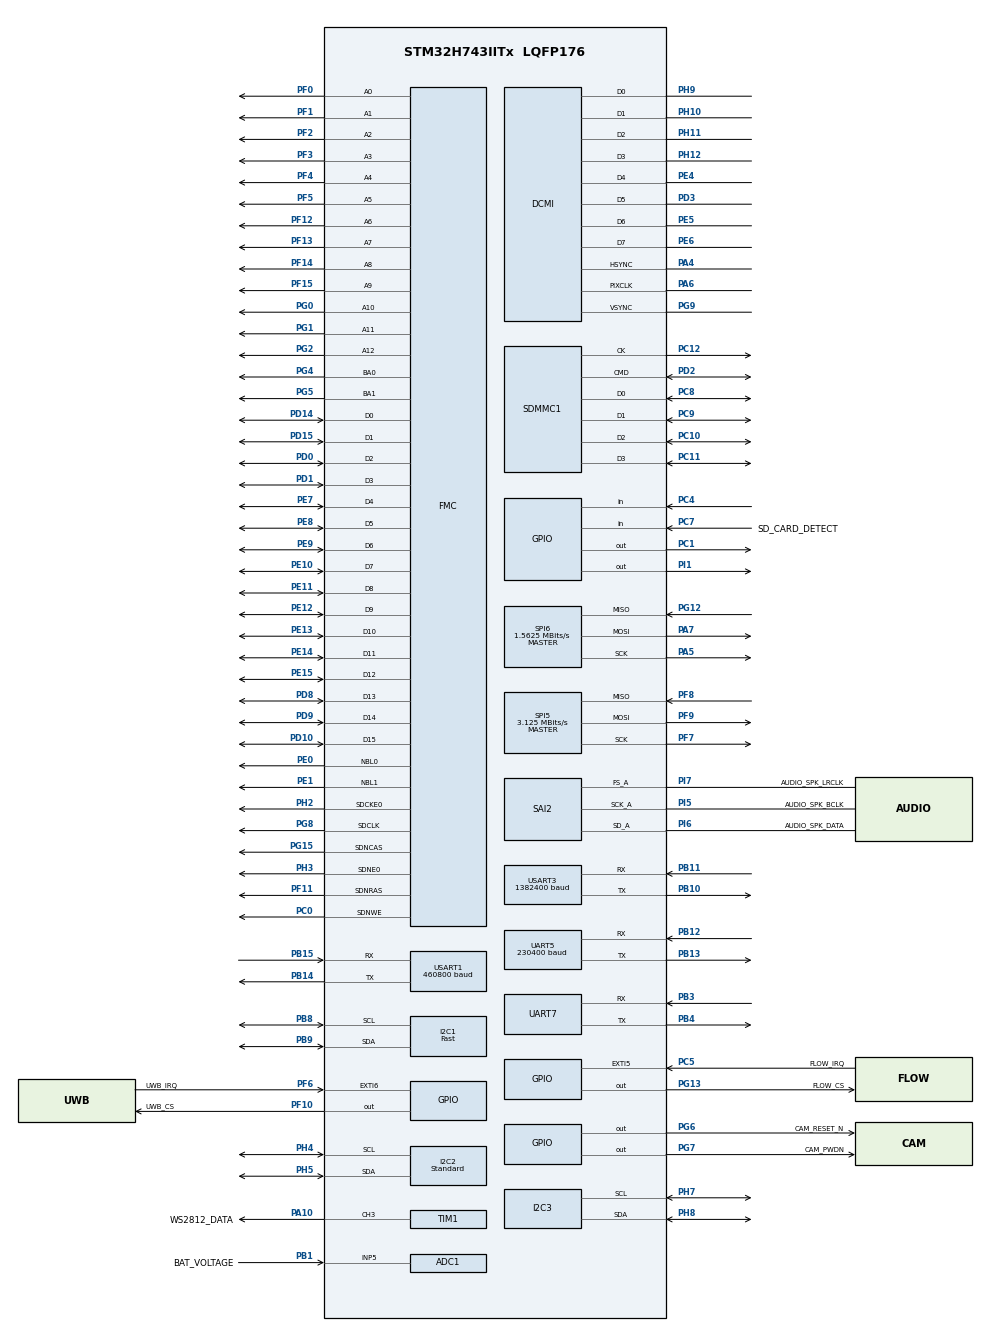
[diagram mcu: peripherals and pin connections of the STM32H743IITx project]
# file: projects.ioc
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ADC1.Channel-1\#ChannelRegularConversion=ADC_CHANNEL_5
ADC1.ClockPrescaler=ADC_CLOCK_ASYNC_DIV4
ADC1.NbrOfConversionFlag=1
ADC1.OffsetNumber-1\#ChannelRegularConversion=ADC_OFFSET_NONE
ADC1.OffsetSignedSaturation-1\#ChannelRegularConversion=DISABLE
ADC1.Rank-1\#ChannelRegularConversion=1
ADC1.SamplingTime-1\#ChannelRegularConversion=ADC_SAMPLETIME_387CYCLES_5
ADC1.master=1
CORTEX_M7.CPU_DCache=Disabled
CORTEX_M7.CPU_ICache=Enabled
CORTEX_M7.default_mode_Activation=1
DCMI.ByteSelectMode=DCMI_BSM_ALL
DCMI.CaptureRate=DCMI_CR_ALL_FRAME
DCMI.HSPolarity=DCMI_HSPOLARITY_LOW
DCMI.JPEGMode=DCMI_JPEG_ENABLE
DCMI.LineSelectMode=DCMI_LSM_ALL
DCMI.PCKPolarity=DCMI_PCKPOLARITY_RISING
DCMI.VSPolarity=DCMI_VSPOLARITY_LOW
Dma.DCMI.0.Direction=DMA_PERIPH_TO_MEMORY
Dma.DCMI.0.EventEnable=DISABLE
Dma.DCMI.0.FIFOMode=DMA_FIFOMODE_ENABLE
Dma.DCMI.0.FIFOThreshold=DMA_FIFO_THRESHOLD_FULL
Dma.DCMI.0.Instance=DMA1_Stream0
Dma.DCMI.0.MemBurst=DMA_MBURST_INC4
Dma.DCMI.0.MemDataAlignment=DMA_MDATAALIGN_WORD
Dma.DCMI.0.MemInc=DMA_MINC_ENABLE
Dma.DCMI.0.Mode=DMA_NORMAL
Dma.DCMI.0.PeriphBurst=DMA_PBURST_SINGLE
Dma.DCMI.0.PeriphDataAlignment=DMA_PDATAALIGN_WORD
Dma.DCMI.0.PeriphInc=DMA_PINC_DISABLE
Dma.DCMI.0.Polarity=HAL_DMAMUX_REQ_GEN_RISING
Dma.DCMI.0.Priority=DMA_PRIORITY_VERY_HIGH
Dma.DCMI.0.RequestNumber=1
Dma.DCMI.0.SignalID=NONE
Dma.DCMI.0.SyncEnable=DISABLE
Dma.DCMI.0.SyncPolarity=HAL_DMAMUX_SYNC_NO_EVENT
Dma.DCMI.0.SyncRequestNumber=1
Dma.DCMI.0.SyncSignalID=NONE
Dma.Request0=DCMI
Dma.Request1=SAI2_A
Dma.Request2=TIM1_CH3
Dma.Request3=USART1_RX
Dma.Request4=USART1_TX
Dma.Request5=UART5_RX
Dma.SAI2_A.1.Direction=DMA_MEMORY_TO_PERIPH
Dma.SAI2_A.1.EventEnable=DISABLE
Dma.SAI2_A.1.FIFOMode=DMA_FIFOMODE_DISABLE
Dma.SAI2_A.1.Instance=DMA1_Stream4
Dma.SAI2_A.1.MemDataAlignment=DMA_MDATAALIGN_HALFWORD
Dma.SAI2_A.1.MemInc=DMA_MINC_ENABLE
Dma.SAI2_A.1.Mode=DMA_CIRCULAR
Dma.SAI2_A.1.PeriphDataAlignment=DMA_PDATAALIGN_HALFWORD
Dma.SAI2_A.1.PeriphInc=DMA_PINC_DISABLE
Dma.SAI2_A.1.Polarity=HAL_DMAMUX_REQ_GEN_RISING
Dma.SAI2_A.1.Priority=DMA_PRIORITY_HIGH
Dma.SAI2_A.1.RequestNumber=1
Dma.SAI2_A.1.SignalID=NONE
Dma.SAI2_A.1.SyncEnable=DISABLE
Dma.SAI2_A.1.SyncPolarity=HAL_DMAMUX_SYNC_NO_EVENT
Dma.SAI2_A.1.SyncRequestNumber=1
Dma.SAI2_A.1.SyncSignalID=NONE
Dma.TIM1_CH3.2.Direction=DMA_MEMORY_TO_PERIPH
Dma.TIM1_CH3.2.EventEnable=DISABLE
Dma.TIM1_CH3.2.FIFOMode=DMA_FIFOMODE_DISABLE
Dma.TIM1_CH3.2.Instance=DMA1_Stream3
Dma.TIM1_CH3.2.MemDataAlignment=DMA_MDATAALIGN_HALFWORD
Dma.TIM1_CH3.2.MemInc=DMA_MINC_ENABLE
Dma.TIM1_CH3.2.Mode=DMA_NORMAL
Dma.TIM1_CH3.2.PeriphDataAlignment=DMA_PDATAALIGN_HALFWORD
Dma.TIM1_CH3.2.PeriphInc=DMA_PINC_DISABLE
Dma.TIM1_CH3.2.Polarity=HAL_DMAMUX_REQ_GEN_RISING
Dma.TIM1_CH3.2.Priority=DMA_PRIORITY_HIGH
Dma.TIM1_CH3.2.RequestNumber=1
Dma.TIM1_CH3.2.SignalID=NONE
Dma.TIM1_CH3.2.SyncEnable=DISABLE
Dma.TIM1_CH3.2.SyncPolarity=HAL_DMAMUX_SYNC_NO_EVENT
Dma.TIM1_CH3.2.SyncRequestNumber=1
Dma.TIM1_CH3.2.SyncSignalID=NONE
Dma.UART5_RX.5.Direction=DMA_PERIPH_TO_MEMORY
Dma.UART5_RX.5.EventEnable=DISABLE
Dma.UART5_RX.5.FIFOMode=DMA_FIFOMODE_DISABLE
Dma.UART5_RX.5.Instance=DMA1_Stream5
Dma.UART5_RX.5.MemDataAlignment=DMA_MDATAALIGN_BYTE
Dma.UART5_RX.5.MemInc=DMA_MINC_ENABLE
Dma.UART5_RX.5.Mode=DMA_CIRCULAR
Dma.UART5_RX.5.PeriphDataAlignment=DMA_PDATAALIGN_BYTE
Dma.UART5_RX.5.PeriphInc=DMA_PINC_DISABLE
Dma.UART5_RX.5.Polarity=HAL_DMAMUX_REQ_GEN_RISING
Dma.UART5_RX.5.Priority=DMA_PRIORITY_LOW
Dma.UART5_RX.5.RequestNumber=1
Dma.UART5_RX.5.SignalID=NONE
Dma.UART5_RX.5.SyncEnable=DISABLE
Dma.UART5_RX.5.SyncPolarity=HAL_DMAMUX_SYNC_NO_EVENT
Dma.UART5_RX.5.SyncRequestNumber=1
Dma.UART5_RX.5.SyncSignalID=NONE
Dma.USART1_RX.3.Direction=DMA_PERIPH_TO_MEMORY
Dma.USART1_RX.3.EventEnable=DISABLE
Dma.USART1_RX.3.FIFOMode=DMA_FIFOMODE_DISABLE
Dma.USART1_RX.3.Instance=DMA1_Stream1
Dma.USART1_RX.3.MemDataAlignment=DMA_MDATAALIGN_BYTE
Dma.USART1_RX.3.MemInc=DMA_MINC_ENABLE
Dma.USART1_RX.3.Mode=DMA_CIRCULAR
Dma.USART1_RX.3.PeriphDataAlignment=DMA_PDATAALIGN_BYTE
Dma.USART1_RX.3.PeriphInc=DMA_PINC_DISABLE
Dma.USART1_RX.3.Polarity=HAL_DMAMUX_REQ_GEN_RISING
Dma.USART1_RX.3.Priority=DMA_PRIORITY_HIGH
Dma.USART1_RX.3.RequestNumber=1
Dma.USART1_RX.3.SignalID=NONE
Dma.USART1_RX.3.SyncEnable=DISABLE
Dma.USART1_RX.3.SyncPolarity=HAL_DMAMUX_SYNC_NO_EVENT
Dma.USART1_RX.3.SyncRequestNumber=1
Dma.USART1_RX.3.SyncSignalID=NONE
Dma.USART1_TX.4.Direction=DMA_MEMORY_TO_PERIPH
Dma.USART1_TX.4.EventEnable=DISABLE
Dma.USART1_TX.4.FIFOMode=DMA_FIFOMODE_DISABLE
Dma.USART1_TX.4.Instance=DMA1_Stream2
Dma.USART1_TX.4.MemDataAlignment=DMA_MDATAALIGN_BYTE
Dma.USART1_TX.4.MemInc=DMA_MINC_ENABLE
Dma.USART1_TX.4.Mode=DMA_NORMAL
Dma.USART1_TX.4.PeriphDataAlignment=DMA_PDATAALIGN_BYTE
Dma.USART1_TX.4.PeriphInc=DMA_PINC_DISABLE
Dma.USART1_TX.4.Polarity=HAL_DMAMUX_REQ_GEN_RISING
Dma.USART1_TX.4.Priority=DMA_PRIORITY_LOW
Dma.USART1_TX.4.RequestNumber=1
Dma.USART1_TX.4.SignalID=NONE
Dma.USART1_TX.4.SyncEnable=DISABLE
Dma.USART1_TX.4.SyncPolarity=HAL_DMAMUX_SYNC_NO_EVENT
Dma.USART1_TX.4.SyncRequestNumber=1
Dma.USART1_TX.4.SyncSignalID=NONE
FATFS.USE_DMA_CODE_SD=1
FATFS._FS_NORTC=1
FATFS._FS_REENTRANT=1
FATFS._FS_LOCK=4
FATFS._MAX_SS=512
FATFS._MIN_SS=512
FATFS._NORTC_MDAY=8
FATFS._NORTC_MON=10
FATFS._NORTC_YEAR=2026
FATFS._USE_LFN=0
FMC.CASLatency1=FMC_SDRAM_CAS_LATENCY_2
FMC.ColumnBitsNumber1=FMC_SDRAM_COLUMN_BITS_NUM_9
FMC.ExitSelfRefreshDelay1=8
FMC.LoadToActiveDelay1=2
FMC.RCDDelay1=2
FMC.RPDelay1=2
FMC.ReadBurst1=FMC_SDRAM_RBURST_ENABLE
FMC.ReadPipeDelay1=FMC_SDRAM_RPIPE_DELAY_1
FMC.RowBitsNumber1=FMC_SDRAM_ROW_BITS_NUM_13
FMC.RowCycleDelay1=7
FMC.SDClockPeriod1=FMC_SDRAM_CLOCK_PERIOD_2
FMC.SDClockPeriod2=FMC_SDRAM_CLOCK_PERIOD_2
FMC.SelfRefreshTime1=5
FMC.WriteRecoveryTime1=3
FREERTOS.Mutexes01=i2c1Mutex,Dynamic,NULL
FREERTOS.Tasks01=defaultTask,24,512,StartDefaultTask,Default,NULL,Dynamic,NULL,NULL;uart_bluetooth,8,512,BLUETOOTH,Default,NULL,Dynamic,NULL,NULL;led_blink,8,128,led_blink1,Default,NULL,Dynamic,NULL,NULL;mavlinkTask,32,1024,StartMavlinkTask,Default,NULL,Dynamic,NULL,NULL;gpsTask,24,512,StartGpsTask,Default,NULL,Dynamic,NULL,NULL;audio1,24,512,audio,Default,NULL,Dynamic,NULL,NULL;thermalTask,8,2048,StartThermalTask,Default,NULL,Dynamic,NULL,NULL
FREERTOS.configCHECK_FOR_STACK_OVERFLOW=2
FREERTOS.configTOTAL_HEAP_SIZE=98304
FREERTOS.configUSE_MALLOC_FAILED_HOOK=1
FREERTOS.configUSE_NEWLIB_REENTRANT=0
I2C1.I2C_Speed_Mode=I2C_Fast
I2C1.Speed=400
I2C1.Timing=0x009034B6
I2C2.I2C_Fall_Time=100
I2C2.I2C_Rise_Time=100
I2C2.I2C_Speed_Mode=I2C_Standard
I2C2.Speed=100
I2C2.Timing=0x20B182BE
I2C3.Timing=0x10C0ECFF
Mcu.Family=STM32H7
Mcu.Name=STM32H743IITx
Mcu.Package=LQFP176
NVIC.DCMI_IRQn=true\:5\:0\:false\:false\:true\:true\:false\:true\:true
NVIC.DMA1_Stream0_IRQn=true\:5\:0\:false\:false\:true\:true\:false\:true\:true
NVIC.DMA1_Stream1_IRQn=true\:5\:0\:false\:false\:true\:true\:false\:true\:true
NVIC.DMA1_Stream2_IRQn=true\:5\:0\:false\:false\:true\:true\:false\:true\:true
NVIC.DMA1_Stream3_IRQn=true\:5\:0\:false\:false\:true\:true\:false\:true\:true
NVIC.DMA1_Stream4_IRQn=true\:5\:0\:false\:false\:true\:true\:false\:true\:true
NVIC.DMA1_Stream5_IRQn=true\:5\:0\:false\:false\:true\:true\:false\:true\:true
NVIC.EXTI9_5_IRQn=true\:5\:0\:false\:false\:true\:true\:false\:true\:true
NVIC.PriorityGroup=NVIC_PRIORITYGROUP_4
NVIC.SDMMC1_IRQn=true\:5\:0\:false\:false\:true\:true\:false\:true\:true
NVIC.TIM2_IRQn=true\:15\:0\:false\:false\:true\:false\:false\:true\:true
NVIC.TimeBase=TIM2_IRQn
NVIC.TimeBaseIP=TIM2
NVIC.UART5_IRQn=true\:5\:0\:false\:false\:true\:true\:false\:true\:true
NVIC.UART7_IRQn=true\:5\:0\:false\:false\:true\:true\:false\:true\:true
NVIC.USART1_IRQn=true\:5\:0\:false\:false\:true\:true\:false\:true\:true
PA10.GPIO_Label=WS2812_DATA
PA10.GPIO_Speed=GPIO_SPEED_FREQ_HIGH
PA10.Signal=S_TIM1_CH3
PA13\ (JTMS/SWDIO).Mode=Serial_Wire
PA13\ (JTMS/SWDIO).Signal=DEBUG_JTMS-SWDIO
PA14\ (JTCK/SWCLK).Mode=Serial_Wire
PA14\ (JTCK/SWCLK).Signal=DEBUG_JTCK-SWCLK
PA4.Mode=Slave_8_bits_External_Synchro
PA4.Signal=DCMI_HSYNC
PA5.Mode=Full_Duplex_Master
PA5.Signal=SPI6_SCK
PA6.Mode=Slave_8_bits_External_Synchro
PA6.Signal=DCMI_PIXCLK
PA7.Mode=Full_Duplex_Master
PA7.Signal=SPI6_MOSI
PB1.GPIO_Label=BAT_VOLTAGE
PB1.Signal=ADCx_INP5
PB10.Mode=Asynchronous
PB10.Signal=USART3_TX
PB11.Mode=Asynchronous
PB11.Signal=USART3_RX
PB12.Mode=Asynchronous
PB12.Signal=UART5_RX
PB13.Mode=Asynchronous
PB13.Signal=UART5_TX
PB14.Mode=Asynchronous
PB14.Signal=USART1_TX
PB15.Mode=Asynchronous
PB15.Signal=USART1_RX
PB3\ (JTDO/TRACESWO).Mode=Asynchronous
PB3\ (JTDO/TRACESWO).Signal=UART7_RX
PB4\ (NJTRST).Mode=Asynchronous
PB4\ (NJTRST).Signal=UART7_TX
PB8.Mode=I2C
PB8.Signal=I2C1_SCL
PB9.Mode=I2C
PB9.Signal=I2C1_SDA
PC0.Signal=FMC_SDNWE
PC1.GPIO_ModeDefaultOutputPP=GPIO_MODE_OUTPUT_OD
PC1.GPIO_PuPd=GPIO_NOPULL
PC1.PinState=GPIO_PIN_RESET
PC1.Signal=GPIO_Output
PC10.Mode=SD_4_bits_Wide_bus
PC10.Signal=SDMMC1_D2
PC11.Mode=SD_4_bits_Wide_bus
PC11.Signal=SDMMC1_D3
PC12.Mode=SD_4_bits_Wide_bus
PC12.Signal=SDMMC1_CK
PC4.GPIO_PuPd=GPIO_PULLUP
PC4.Signal=GPIO_Input
PC5.GPIO_Label=FLOW_IRQ
PC5.GPIO_ModeDefaultEXTI=GPIO_MODE_IT_FALLING
PC5.GPIO_PuPd=GPIO_PULLUP
PC5.Signal=GPXTI5
PC7.GPIO_Label=SD_CARD_DETECT
PC7.GPIO_PuPd=GPIO_PULLUP
PC7.Signal=GPIO_Input
PC8.Mode=SD_4_bits_Wide_bus
PC8.Signal=SDMMC1_D0
PC9.Mode=SD_4_bits_Wide_bus
PC9.Signal=SDMMC1_D1
PD0.Signal=FMC_D2_DA2
PD1.Signal=FMC_D3_DA3
PD10.Signal=FMC_D15_DA15
PD14.Signal=FMC_D0_DA0
PD15.Signal=FMC_D1_DA1
PD2.Mode=SD_4_bits_Wide_bus
PD2.Signal=SDMMC1_CMD
PD3.Mode=Slave_8_bits_External_Synchro
PD3.Signal=DCMI_D5
PD8.Signal=FMC_D13_DA13
PD9.Signal=FMC_D14_DA14
PE0.Signal=FMC_NBL0
PE1.Signal=FMC_NBL1
PE10.Signal=FMC_D7_DA7
PE11.Signal=FMC_D8_DA8
PE12.Signal=FMC_D9_DA9
PE13.Signal=FMC_D10_DA10
PE14.Signal=FMC_D11_DA11
PE15.Signal=FMC_D12_DA12
PE4.Mode=Slave_8_bits_External_Synchro
PE4.Signal=DCMI_D4
PE5.Mode=Slave_8_bits_External_Synchro
PE5.Signal=DCMI_D6
PE6.Mode=Slave_8_bits_External_Synchro
PE6.Signal=DCMI_D7
PE7.Signal=FMC_D4_DA4
PE8.Signal=FMC_D5_DA5
PE9.Signal=FMC_D6_DA6
PF0.Signal=FMC_A0
PF1.Signal=FMC_A1
PF10.GPIO_Label=UWB_CS
PF10.GPIO_Speed=GPIO_SPEED_FREQ_HIGH
PF10.PinState=GPIO_PIN_SET
PF10.Signal=GPIO_Output
PF11.Signal=FMC_SDNRAS
PF12.Signal=FMC_A6
PF13.Signal=FMC_A7
PF14.Signal=FMC_A8
PF15.Signal=FMC_A9
PF2.Signal=FMC_A2
PF3.Signal=FMC_A3
PF4.Signal=FMC_A4
PF5.Signal=FMC_A5
PF6.GPIO_Label=UWB_IRQ
PF6.GPIO_ModeDefaultEXTI=GPIO_MODE_IT_RISING
PF6.GPIO_PuPd=GPIO_NOPULL
PF6.Signal=GPXTI6
PF7.Mode=Full_Duplex_Master
PF7.Signal=SPI5_SCK
PF8.Mode=Full_Duplex_Master
PF8.Signal=SPI5_MISO
PF9.Mode=Full_Duplex_Master
PF9.Signal=SPI5_MOSI
PG0.Signal=FMC_A10
PG1.Signal=FMC_A11
PG12.Mode=Full_Duplex_Master
PG12.Signal=SPI6_MISO
PG13.GPIO_Label=FLOW_CS
PG13.GPIO_Speed=GPIO_SPEED_FREQ_HIGH
PG13.PinState=GPIO_PIN_SET
PG13.Signal=GPIO_Output
PG15.Signal=FMC_SDNCAS
PG2.Signal=FMC_A12
PG4.Signal=FMC_A14_BA0
PG5.Signal=FMC_A15_BA1
PG6.GPIO_Label=CAM_RESET_N
PG6.GPIO_PuPd=GPIO_NOPULL
PG6.GPIO_Speed=GPIO_SPEED_FREQ_LOW
PG6.PinState=GPIO_PIN_RESET
PG6.Signal=GPIO_Output
PG7.GPIO_Label=CAM_PWDN
PG7.GPIO_PuPd=GPIO_NOPULL
PG7.GPIO_Speed=GPIO_SPEED_FREQ_LOW
PG7.PinState=GPIO_PIN_SET
PG7.Signal=GPIO_Output
PG8.Signal=FMC_SDCLK
PG9.Mode=Slave_8_bits_External_Synchro
PG9.Signal=DCMI_VSYNC
PH10.Mode=Slave_8_bits_External_Synchro
PH10.Signal=DCMI_D1
PH11.Mode=Slave_8_bits_External_Synchro
PH11.Signal=DCMI_D2
PH12.Mode=Slave_8_bits_External_Synchro
PH12.Signal=DCMI_D3
PH2.Mode=SdramChipSelect1_1
PH2.Signal=FMC_SDCKE0
PH3.Mode=SdramChipSelect1_1
PH3.Signal=FMC_SDNE0
PH4.Mode=I2C
PH4.Signal=I2C2_SCL
PH5.Mode=I2C
PH5.Signal=I2C2_SDA
PH7.Mode=I2C
PH7.Signal=I2C3_SCL
PH8.Mode=I2C
PH8.Signal=I2C3_SDA
PH9.Mode=Slave_8_bits_External_Synchro
PH9.Signal=DCMI_D0
PI1.PinState=GPIO_PIN_SET
PI1.Signal=GPIO_Output
PI5.GPIO_Label=AUDIO_SPK_BCLK
PI5.GPIO_Speed=GPIO_SPEED_FREQ_HIGH
PI5.Mode=SAI_A_Master
PI5.Signal=SAI2_SCK_A
PI6.GPIO_Label=AUDIO_SPK_DATA
PI6.GPIO_Speed=GPIO_SPEED_FREQ_HIGH
PI6.Mode=SAI_A_Master
PI6.Signal=SAI2_SD_A
PI7.GPIO_Label=AUDIO_SPK_LRCLK
PI7.GPIO_Speed=GPIO_SPEED_FREQ_HIGH
PI7.Mode=SAI_A_Master
PI7.Signal=SAI2_FS_A
ProjectManager.HeapSize=0x200
ProjectManager.StackSize=0x400
ProjectManager.TargetToolchain=CMake
RCC.ADCCLockSelection=RCC_ADCCLKSOURCE_PLL2
RCC.ADCFreq_Value=80000000
RCC.APB1Freq_Value=100000000
RCC.APB2Freq_Value=100000000
RCC.APB3Freq_Value=100000000
RCC.APB4Freq_Value=100000000
RCC.CortexFreq_Value=400000000
RCC.D1PPRE=RCC_APB3_DIV2
RCC.D2PPRE1=RCC_APB1_DIV2
RCC.D2PPRE2=RCC_APB2_DIV2
RCC.D3PPRE=RCC_APB4_DIV2
RCC.DIVM1=4
RCC.DIVM2=4
RCC.DIVM3=4
RCC.DIVN1=50
RCC.DIVN2=10
RCC.DIVN3=12
RCC.DIVP3=4
RCC.DIVQ1=4
RCC.DIVQ3=4
RCC.DIVR3=8
RCC.HCLKFreq_Value=200000000
RCC.HPRE=RCC_HCLK_DIV2
RCC.LSEState=RCC_LSE_OFF
RCC.PLL1_VCI_Range=RCC_PLL1VCIRANGE_3
RCC.PLL1_VCO_SEL=RCC_PLL1VCOWIDE
RCC.PLL2FRACN=0
RCC.PLL2_VCI_Range=RCC_PLL2VCIRANGE_3
RCC.PLL2_VCO_SEL=RCC_PLL2VCOMEDIUM
RCC.PLL3FRACN=2359
RCC.PLL3_VCI_Range=RCC_PLL3VCIRANGE_3
RCC.PLL3_VCO_SEL=RCC_PLL3VCOMEDIUM
RCC.PLLFRACN=0
RCC.PLLSourceVirtual=RCC_PLLSOURCE_HSI
RCC.SAI23CLockSelection=RCC_SAI23CLKSOURCE_PLL3
RCC.SDMMC1CLockSelection=RCC_SDMMCCLKSOURCE_PLL
RCC.SYSCLKFreq_VALUE=400000000
RCC.SYSCLKSource=RCC_SYSCLKSOURCE_PLLCLK
RCC.USBCLockSelection=RCC_USBCLKSOURCE_HSI48
RCC.USBFreq_Value=48000000
SAI2.ActiveFrameLength=16
SAI2.ActiveFrameLength-SAI_A_Master=16
SAI2.AudioFrequency=SAI_AUDIO_FREQUENCY_48K
SAI2.AudioFrequency-SAI_A_Master=SAI_AUDIO_FREQUENCY_48K
SAI2.AudioMode=SAI_MODEMASTER_TX
SAI2.ClockStrobing=SAI_CLOCKSTROBING_FALLINGEDGE
SAI2.ClockStrobing-SAI_A_Master=SAI_CLOCKSTROBING_FALLINGEDGE
SAI2.DataSize=SAI_DATASIZE_16
SAI2.DataSize-SAI_A_Master=SAI_DATASIZE_16
SAI2.ErrorAudioFreq-SAI_A_Master=0.0 %
SAI2.FIFOThreshold=SAI_FIFOTHRESHOLD_1QF
SAI2.FSDefinition=SAI_FS_CHANNEL_IDENTIFICATION
SAI2.FSDefinition-SAI_A_Master=SAI_FS_CHANNEL_IDENTIFICATION
SAI2.FSOffset=SAI_FS_BEFOREFIRSTBIT
SAI2.FSOffset-SAI_A_Master=SAI_FS_BEFOREFIRSTBIT
SAI2.FSPolarity=SAI_FS_ACTIVE_LOW
SAI2.FSPolarity-SAI_A_Master=SAI_FS_ACTIVE_LOW
SAI2.FirstBit=SAI_FIRSTBIT_MSB
SAI2.FirstBit-SAI_A_Master=SAI_FIRSTBIT_MSB
SAI2.FirstBitOffset=0
SAI2.FirstBitOffset-SAI_A_Master=0
SAI2.FrameLength=32
SAI2.FrameLength-SAI_A_Master=32
SAI2.InitProtocol=Disable
SAI2.InitProtocol-SAI_A_Master=Disable
SAI2.Instance-SAI_A_Master=SAI$Index_Block_A
SAI2.MClockEnable-SAI_A_Master=SAI_MASTERCLOCK_DISABLE
SAI2.NoDivider=SAI_MASTERDIVIDER_ENABLE
SAI2.OutputDrive=SAI_OUTPUTDRIVE_ENABLE
SAI2.Protocol=SAI_FREE_PROTOCOL
SAI2.Protocol-SAI_A_Master=SAI_FREE_PROTOCOL
SAI2.RealAudioFreq-SAI_A_Master=47.999 KHz
SAI2.SlotActive=0x0000FFFF
SAI2.SlotActive-SAI_A_Master=0x0000FFFF
SAI2.SlotNumber=2
SAI2.SlotNumber-SAI_A_Master=2
SAI2.SlotSize=SAI_SLOTSIZE_16B
SAI2.SlotSize-SAI_A_Master=SAI_SLOTSIZE_16B
SAI2.Synchro_A=SAI_ASYNCHRONOUS
SAI2.VirtualMode-SAI_A_Master=VM_MASTER
SAI2.VirtualProtocol=VM_NO_PROTOCOL
SAI2.VirtualProtocol-SAI_A_Master=VM_NO_PROTOCOL
SAI2.VirtualSlotActive=SAI_SLOTACTIVE_ALL
SAI2.VirtualSlotActive-SAI_A_Master=SAI_SLOTACTIVE_ALL
SDMMC1.ClockDiv=4
SDMMC1.ClockEdge=SDMMC_CLOCK_EDGE_RISING
SDMMC1.HardwareFlowControl=SDMMC_HARDWARE_FLOW_CONTROL_ENABLE
SH.ADCx_INP5.0=ADC1_INP5,IN5-Single-Ended
SH.FMC_A0.0=FMC_A0,13b-sda1
SH.FMC_A1.0=FMC_A1,13b-sda1
SH.FMC_A10.0=FMC_A10,13b-sda1
SH.FMC_A11.0=FMC_A11,13b-sda1
SH.FMC_A12.0=FMC_A12,13b-sda1
SH.FMC_A14_BA0.0=FMC_BA0,FourSdramBanks1
SH.FMC_A15_BA1.0=FMC_BA1,FourSdramBanks1
SH.FMC_A2.0=FMC_A2,13b-sda1
SH.FMC_A3.0=FMC_A3,13b-sda1
SH.FMC_A4.0=FMC_A4,13b-sda1
SH.FMC_A5.0=FMC_A5,13b-sda1
SH.FMC_A6.0=FMC_A6,13b-sda1
SH.FMC_A7.0=FMC_A7,13b-sda1
SH.FMC_A8.0=FMC_A8,13b-sda1
SH.FMC_A9.0=FMC_A9,13b-sda1
SH.FMC_D0_DA0.0=FMC_D0,sd-16b-d1
SH.FMC_D10_DA10.0=FMC_D10,sd-16b-d1
SH.FMC_D11_DA11.0=FMC_D11,sd-16b-d1
SH.FMC_D12_DA12.0=FMC_D12,sd-16b-d1
SH.FMC_D13_DA13.0=FMC_D13,sd-16b-d1
SH.FMC_D14_DA14.0=FMC_D14,sd-16b-d1
SH.FMC_D15_DA15.0=FMC_D15,sd-16b-d1
SH.FMC_D1_DA1.0=FMC_D1,sd-16b-d1
SH.FMC_D2_DA2.0=FMC_D2,sd-16b-d1
SH.FMC_D3_DA3.0=FMC_D3,sd-16b-d1
SH.FMC_D4_DA4.0=FMC_D4,sd-16b-d1
SH.FMC_D5_DA5.0=FMC_D5,sd-16b-d1
SH.FMC_D6_DA6.0=FMC_D6,sd-16b-d1
SH.FMC_D7_DA7.0=FMC_D7,sd-16b-d1
SH.FMC_D8_DA8.0=FMC_D8,sd-16b-d1
SH.FMC_D9_DA9.0=FMC_D9,sd-16b-d1
SH.FMC_NBL0.0=FMC_NBL0,Sd2ByteEnable1
SH.FMC_NBL1.0=FMC_NBL1,Sd2ByteEnable1
SH.FMC_SDCLK.0=FMC_SDCLK,13b-sda1
SH.FMC_SDNCAS.0=FMC_SDNCAS,13b-sda1
SH.FMC_SDNRAS.0=FMC_SDNRAS,13b-sda1
SH.FMC_SDNWE.0=FMC_SDNWE,13b-sda1
SH.S_TIM1_CH3.0=TIM1_CH3,PWM Generation3 CH3
SPI5.BaudRatePrescaler=SPI_BAUDRATEPRESCALER_32
SPI5.CLKPhase=SPI_PHASE_1EDGE
SPI5.CLKPolarity=SPI_POLARITY_LOW
SPI5.CalculateBaudRate=3.125 MBits/s
SPI5.DataSize=SPI_DATASIZE_8BIT
SPI5.Direction=SPI_DIRECTION_2LINES
SPI5.FirstBit=SPI_FIRSTBIT_MSB
SPI5.Mode=SPI_MODE_MASTER
SPI5.NSS=SPI_NSS_SOFT
SPI5.NSSPMode=SPI_NSS_PULSE_DISABLE
SPI5.VirtualType=VM_MASTER
SPI6.BaudRatePrescaler=SPI_BAUDRATEPRESCALER_64
SPI6.CLKPhase=SPI_PHASE_2EDGE
SPI6.CLKPolarity=SPI_POLARITY_HIGH
SPI6.CalculateBaudRate=1.5625 MBits/s
SPI6.DataSize=SPI_DATASIZE_8BIT
SPI6.Direction=SPI_DIRECTION_2LINES
SPI6.FirstBit=SPI_FIRSTBIT_MSB
SPI6.MasterKeepIOState=SPI_MASTER_KEEP_IO_STATE_ENABLE
SPI6.Mode=SPI_MODE_MASTER
SPI6.NSS=SPI_NSS_SOFT
SPI6.NSSPMode=SPI_NSS_PULSE_DISABLE
SPI6.VirtualType=VM_MASTER
TIM1.AutoReloadPreload=TIM_AUTORELOAD_PRELOAD_ENABLE
TIM1.Channel-PWM\ Generation3\ CH3=TIM_CHANNEL_3
TIM1.CounterMode=TIM_COUNTERMODE_UP
TIM1.OCMode_PWM-PWM\ Generation3\ CH3=TIM_OCMODE_PWM1
TIM1.OCPolarity_3=TIM_OCPOLARITY_HIGH
TIM1.Period=79
TIM1.Prescaler=0
TIM1.Pulse-PWM\ Generation3\ CH3=0
UART5.BaudRate=230400
UART5.Mode=MODE_TX_RX
UART5.OverSampling=UART_OVERSAMPLING_16
UART5.Parity=PARITY_NONE
UART5.StopBits=UART_STOPBITS_1
UART5.WordLength=WORDLENGTH_8B
USART1.BaudRate=460800
USART1.Mode=MODE_TX_RX
USART1.OverSampling=UART_OVERSAMPLING_16
USART1.Parity=PARITY_NONE
USART1.StopBits=STOPBITS_1
USART1.VirtualMode=VM_ASYNC
USART1.VirtualMode-Asynchronous=VM_ASYNC
USART1.WordLength=WORDLENGTH_8B
USART3.BaudRate=1382400
USART3.VirtualMode-Asynchronous=VM_ASYNC
VP_FATFS_VS_SDIO.Mode=SDIO
VP_FREERTOS_VS_CMSIS_V2.Mode=CMSIS_V2
VP_MEMORYMAP_VS_MEMORYMAP.Mode=CurAppReg
VP_SYS_VS_tim2.Mode=TIM2
VP_TIM1_VS_ClockSourceINT.Mode=Internal
board=custom

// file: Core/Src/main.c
/* USER CODE BEGIN Header */
/**
  ******************************************************************************
  * @file           : main.c
  * @brief          : Main program body
  ******************************************************************************
  * @attention
  *
  * Copyright (c) 2026 STMicroelectronics.
  * All rights reserved.
  *
  * This software is licensed under terms that can be found in the LICENSE file
  * in the root directory of this software component.
  * If no LICENSE file comes with this software, it is provided AS-IS.
  *
  ******************************************************************************
  */
/* USER CODE END Header */
#include "main.h"
#include "FreeRTOS.h"
#include "cmsis_os2.h"
#include "adc.h"
#include "dcmi.h"
#include "dma.h"
#include "fatfs.h"
#include "i2c.h"
#include "sai.h"
#include "sdmmc.h"
#include "spi.h"
#include "tim.h"
#include "usart.h"
#include "gpio.h"
#include "fmc.h"

/* USER CODE BEGIN Includes */
#if CAMERA_USE_SDRAM
#include "camera_sdram.h"
#endif
#if BOARD_BENCH_TEST
#include "board_bench.h"
#endif

/* USER CODE END Includes */

void SystemClock_Config(void);
static void MPU_Config(void);
void MX_FREERTOS_Init(void);

int main(void)
{

  /* MPU Configuration--------------------------------------------------------*/
  MPU_Config();

  /* Enable the CPU Cache */

  /* Enable I-Cache---------------------------------------------------------*/
  SCB_EnableICache();

  /* MCU Configuration--------------------------------------------------------*/

  /* Reset of all peripherals, Initializes the Flash interface and the Systick. */
  HAL_Init();

  /* USER CODE BEGIN Init */
#if BOARD_BENCH_TEST
  BoardBench_ConfigureMPU();
#endif
  /* USER CODE END Init */

  /* Configure the system clock */
  SystemClock_Config();

  /* USER CODE BEGIN SysInit */
  __HAL_RCC_D2SRAM1_CLK_ENABLE();
  /* DMA buffers and the RTOS heap can extend into SRAM2/SRAM3. */
  __HAL_RCC_D2SRAM2_CLK_ENABLE();
  __HAL_RCC_D2SRAM3_CLK_ENABLE();
  /* USER CODE END SysInit */

  /* Initialize all configured peripherals */
  MX_GPIO_Init();
  MX_DMA_Init();
  MX_FMC_Init();
  MX_DCMI_Init();
  MX_I2C1_Init();
  MX_I2C2_Init();
  MX_SPI5_Init();
  MX_SPI6_Init();
#if !BOARD_BENCH_TEST && !APP_CAMERA_ENABLED
  MX_SDMMC1_SD_Init();
#endif
  MX_SAI2_Init();
  MX_ADC1_Init();
  MX_TIM1_Init();
  MX_UART5_Init();
  MX_USART1_UART_Init();
  MX_FATFS_Init();
  MX_I2C3_Init();
  MX_UART7_Init();
  MX_USART3_UART_Init();
  /* USER CODE BEGIN 2 */
#if CAMERA_USE_SDRAM
  (void)CameraSDRAM_Init(); /* Failure disables camera buffer access only. */
#endif
  /* USER CODE END 2 */

  /* Init scheduler */
  osKernelInitialize();  /* Call init function for freertos objects (in cmsis_os2.c) */
  MX_FREERTOS_Init();

  /* Start scheduler */
  osKernelStart();

  /* We should never get here as control is now taken by the scheduler */

  /* Infinite loop */
  while (1)
  {

  }
}

void SystemClock_Config(void)
{
  RCC_OscInitTypeDef RCC_OscInitStruct = {0};
  RCC_ClkInitTypeDef RCC_ClkInitStruct = {0};

  /** Supply configuration update enable
  */
  HAL_PWREx_ConfigSupply(PWR_LDO_SUPPLY);

  /** Configure the main internal regulator output voltage
  */
  __HAL_PWR_VOLTAGESCALING_CONFIG(PWR_REGULATOR_VOLTAGE_SCALE1);

  while(!__HAL_PWR_GET_FLAG(PWR_FLAG_VOSRDY)) {}

  /** Initializes the RCC Oscillators according to the specified parameters
  * in the RCC_OscInitTypeDef structure.
  */
  RCC_OscInitStruct.OscillatorType = RCC_OSCILLATORTYPE_HSI;
  RCC_OscInitStruct.HSIState = RCC_HSI_DIV1;
  RCC_OscInitStruct.HSICalibrationValue = RCC_HSICALIBRATION_DEFAULT;
  RCC_OscInitStruct.PLL.PLLState = RCC_PLL_ON;
  RCC_OscInitStruct.PLL.PLLSource = RCC_PLLSOURCE_HSI;
  RCC_OscInitStruct.PLL.PLLM = 4;
  RCC_OscInitStruct.PLL.PLLN = 50;
  RCC_OscInitStruct.PLL.PLLP = 2;
  RCC_OscInitStruct.PLL.PLLQ = 4;
  RCC_OscInitStruct.PLL.PLLR = 2;
  RCC_OscInitStruct.PLL.PLLRGE = RCC_PLL1VCIRANGE_3;
  RCC_OscInitStruct.PLL.PLLVCOSEL = RCC_PLL1VCOWIDE;
  RCC_OscInitStruct.PLL.PLLFRACN = 0;
  if (HAL_RCC_OscConfig(&RCC_OscInitStruct) != HAL_OK)
  {
    Error_Handler();
  }

  /** Initializes the CPU, AHB and APB buses clocks
  */
  RCC_ClkInitStruct.ClockType = RCC_CLOCKTYPE_HCLK|RCC_CLOCKTYPE_SYSCLK
                              |RCC_CLOCKTYPE_PCLK1|RCC_CLOCKTYPE_PCLK2
                              |RCC_CLOCKTYPE_D3PCLK1|RCC_CLOCKTYPE_D1PCLK1;
  RCC_ClkInitStruct.SYSCLKSource = RCC_SYSCLKSOURCE_PLLCLK;
  RCC_ClkInitStruct.SYSCLKDivider = RCC_SYSCLK_DIV1;
  RCC_ClkInitStruct.AHBCLKDivider = RCC_HCLK_DIV2;
  RCC_ClkInitStruct.APB3CLKDivider = RCC_APB3_DIV2;
  RCC_ClkInitStruct.APB1CLKDivider = RCC_APB1_DIV2;
  RCC_ClkInitStruct.APB2CLKDivider = RCC_APB2_DIV2;
  RCC_ClkInitStruct.APB4CLKDivider = RCC_APB4_DIV2;

  if (HAL_RCC_ClockConfig(&RCC_ClkInitStruct, FLASH_LATENCY_2) != HAL_OK)
  {
    Error_Handler();
  }
}

 /* MPU Configuration */

void MPU_Config(void)
{
  MPU_Region_InitTypeDef MPU_InitStruct = {0};

  /* Disables the MPU */
  HAL_MPU_Disable();

  /** Initializes and configures the Region and the memory to be protected
  */
  MPU_InitStruct.Enable = MPU_REGION_ENABLE;
  MPU_InitStruct.Number = MPU_REGION_NUMBER0;
  MPU_InitStruct.BaseAddress = 0x0;
  MPU_InitStruct.Size = MPU_REGION_SIZE_4GB;
  MPU_InitStruct.SubRegionDisable = 0x87;
  MPU_InitStruct.TypeExtField = MPU_TEX_LEVEL0;
  MPU_InitStruct.AccessPermission = MPU_REGION_NO_ACCESS;
  MPU_InitStruct.DisableExec = MPU_INSTRUCTION_ACCESS_DISABLE;
  MPU_InitStruct.IsShareable = MPU_ACCESS_SHAREABLE;
  MPU_InitStruct.IsCacheable = MPU_ACCESS_NOT_CACHEABLE;
  MPU_InitStruct.IsBufferable = MPU_ACCESS_NOT_BUFFERABLE;

  HAL_MPU_ConfigRegion(&MPU_InitStruct);
  /* Enables the MPU */
  HAL_MPU_Enable(MPU_PRIVILEGED_DEFAULT);

}

void HAL_TIM_PeriodElapsedCallback(TIM_HandleTypeDef *htim)
{
  if (htim->Instance == TIM6)
  {
    HAL_IncTick();
  }
}

void Error_Handler(void)
{
  __disable_irq();
  while (1)
  {
  }
}

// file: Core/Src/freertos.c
/* USER CODE BEGIN Header */
/**
  ******************************************************************************
  * File Name          : freertos.c
  * Description        : Code for freertos applications
  ******************************************************************************
  * @attention
  *
  * Copyright (c) 2026 STMicroelectronics.
  * All rights reserved.
  *
  * This software is licensed under terms that can be found in the LICENSE file
  * in the root directory of this software component.
  * If no LICENSE file comes with this software, it is provided AS-IS.
  *
  ******************************************************************************
  */
/* USER CODE END Header */

#include "FreeRTOS.h"
#include "FreeRTOSConfig.h"
#include "task.h"
#include "main.h"
#include "FreeRTOS.h"
#include "cmsis_os2.h"
#include "MLX90640_I2C_Driver.h"
#include "thermal_dma.h"
#include "thermal_test.h"
#include "record_control.h"
#include "LD6002_UART.h"
#include "LD6002.h"
#include "uwb_log.h"

/* USER CODE BEGIN Includes */
#include "thermal_test.h"
#include "record_control.h"
#include "mk_app.h"
#include "fc_arm_status.h"
#include "gps_raw.h"
#include "usart.h"
#include <stdio.h>
#include <string.h>
#include "led_strip.h"
#include "fatfs.h"
#include "audio_player.h"
#include "uwb_range.h"
#include "i2c.h"
#include "app_storage.h"
#include "app_log.h"
#if PMW3901_FLOW_MAVLINK
#include "pmw3901.h"
#endif
#if APP_CAMERA_ENABLED
#include "camera_snapshot.h"
#if CAMERA_FLOW_BENCH
#include "camera_flow.h"
#endif
#endif
#if BOARD_BENCH_TEST
#include "board_bench.h"
#endif
/* USER CODE END Includes */

/* USER CODE BEGIN PD */
#define STATUS_LED_COUNT 80U
#define STATUS_LED_STEP 5U
/* USER CODE END PD */

/* USER CODE BEGIN Variables */
#if APP_CAMERA_ENABLED
/* The encoder uses stack scratch heavily. Keep its stack in fast DTCM even
 * though the enlarged shared RTOS heap lives in D2 SRAM. */
static uint64_t camera_task_stack[16384 / sizeof(uint64_t)];
static StaticTask_t camera_task_control;
#endif

/* USER CODE END Variables */
/* Definitions for defaultTask */
osThreadId_t defaultTaskHandle;
const osThreadAttr_t defaultTask_attributes = {
  .name = "defaultTask",
  .stack_size = 512 * 4,
  .priority = (osPriority_t) osPriorityNormal,
};
/* Definitions for uart_bluetooth */
osThreadId_t uart_bluetoothHandle;
const osThreadAttr_t uart_bluetooth_attributes = {
  .name = "uart_bluetooth",
  .stack_size = 512 * 4,
  .priority = (osPriority_t) osPriorityLow,
};
/* Definitions for led_blink */
osThreadId_t led_blinkHandle;
const osThreadAttr_t led_blink_attributes = {
  .name = "led_blink",
  .stack_size = 128 * 4,
  .priority = (osPriority_t) osPriorityLow,
};
/* Definitions for mavlinkTask */
osThreadId_t mavlinkTaskHandle;
const osThreadAttr_t mavlinkTask_attributes = {
  .name = "mavlinkTask",
  .stack_size = 1024 * 4,
  .priority = (osPriority_t) osPriorityAboveNormal,
};
/* Definitions for gpsTask */
osThreadId_t gpsTaskHandle;
const osThreadAttr_t gpsTask_attributes = {
  .name = "gpsTask",
  .stack_size = 512 * 4,
  .priority = (osPriority_t) osPriorityNormal,
};
/* Definitions for audio1 */
osThreadId_t audio1Handle;
const osThreadAttr_t audio1_attributes = {
  .name = "audio1",
  .stack_size = 512 * 4,
  .priority = (osPriority_t) osPriorityNormal,
};
/* Definitions for thermalTask */
osThreadId_t thermalTaskHandle;
const osThreadAttr_t thermalTask_attributes = {
  .name = "thermalTask",
  .stack_size = 2048 * 4,
  .priority = (osPriority_t) osPriorityLow,
};

osThreadId_t LD6002TaskHandle;
extern void LD6002_Task(void *arg);
const osThreadAttr_t LD6002_attributes = {
  .name = "LD6002",
  .stack_size = 1024 * 4,
  .priority = (osPriority_t) osPriorityLow,
};
/* Definitions for i2c1Mutex */
osMutexId_t i2c1MutexHandle;
const osMutexAttr_t i2c1Mutex_attributes = {
  .name = "i2c1Mutex",
  .attr_bits = osMutexPrioInherit,
};

void StartDefaultTask(void *argument);
void BLUETOOTH(void *argument);
void led_blink1(void *argument);
void StartMavlinkTask(void *argument);
void StartGpsTask(void *argument);
void audio(void *argument);
void StartThermalTask(void *argument);
void LD6002(void *argument);

void MX_FREERTOS_Init(void); /* (MISRA C 2004 rule 8.1) */

/* Hook prototypes */
void vApplicationStackOverflowHook(TaskHandle_t task, char *name);
void vApplicationMallocFailedHook(void);

/* USER CODE BEGIN 4 */
void vApplicationStackOverflowHook(TaskHandle_t task, char *name)
{
  (void)task;
  (void)name;
  /* No printf or allocation here: the task stack may already be damaged. */
  Error_Handler();
}
/* USER CODE END 4 */

/* USER CODE BEGIN 5 */
void vApplicationMallocFailedHook(void)
{
  Error_Handler();
}
/* USER CODE END 5 */

void MX_FREERTOS_Init(void) {
  /* USER CODE BEGIN Init */
  if (!AppStorage_Init() || !AppLog_Init()) Error_Handler();
#if APP_CAMERA_ENABLED && CAMERA_FLOW_BENCH
  if (!CameraFlow_Init()) Error_Handler();
#endif
#if BOARD_CAMERA_TEST
  static const osThreadAttr_t camera_attributes = {
      .name = "camera_test", .stack_mem = camera_task_stack,
      .stack_size = sizeof(camera_task_stack),
      .cb_mem = &camera_task_control, .cb_size = sizeof(camera_task_control),
      .priority = osPriorityNormal
  };
  i2c1MutexHandle = osMutexNew(&i2c1Mutex_attributes);
  if (i2c1MutexHandle == NULL ||
      osThreadNew(CameraSnapshot_Task, NULL, &camera_attributes) == NULL)
    Error_Handler();
  return;
#endif
#if BOARD_BENCH_TEST
  static const osThreadAttr_t bench_attributes = {
      .name = "board_bench", .stack_size = 4096, .priority = osPriorityNormal
  };
  if (osThreadNew(BoardBench_Task, NULL, &bench_attributes) == NULL)
    Error_Handler();
  return;
#endif
  UWB_RangeInit();
  MAVLink_AppInit();
  GPS_RawInit();
  if (LED_Strip_Init(STATUS_LED_COUNT) != HAL_OK ||
    LED_Strip_Fill(0, 0, 0, 0) != HAL_OK ||
    LED_Strip_Show() != HAL_OK) {
    Error_Handler();
}
  /* USER CODE END Init */

  /* USER CODE BEGIN RTOS_MUTEX */
  /* CubeMX creates i2c1Mutex immediately after this user section. */
  /* USER CODE END RTOS_MUTEX */

  /* Create the mutex(es) */
  i2c1MutexHandle = osMutexNew(&i2c1Mutex_attributes);

  /* Create the thread(s) */
  /* creation of defaultTask */
  defaultTaskHandle = osThreadNew(StartDefaultTask, NULL, &defaultTask_attributes);

  /* creation of uart_bluetooth */
  uart_bluetoothHandle = osThreadNew(BLUETOOTH, NULL, &uart_bluetooth_attributes);

  /* creation of led_blink */
  led_blinkHandle = osThreadNew(led_blink1, NULL, &led_blink_attributes);

  /* creation of mavlinkTask */
  mavlinkTaskHandle = osThreadNew(StartMavlinkTask, NULL, &mavlinkTask_attributes);

  /* creation of gpsTask */
  gpsTaskHandle = osThreadNew(StartGpsTask, NULL, &gpsTask_attributes);

  /* creation of audio1 */
  audio1Handle = osThreadNew(audio, NULL, &audio1_attributes);

  /* creation of thermalTask */
  thermalTaskHandle = osThreadNew(StartThermalTask, NULL, &thermalTask_attributes);
  /* creation of LD6002Task */
  LD6002TaskHandle = osThreadNew(LD6002, NULL, &LD6002_attributes);

  /* USER CODE BEGIN RTOS_THREADS */
static const osThreadAttr_t uwb_log_attributes = {
    .name = "uwb_log", .stack_size = 2048, .priority = osPriorityLow
};
configASSERT(osThreadNew(UWB_LogTask, NULL, &uwb_log_attributes) != NULL);
  configASSERT(RecordControl_Init());
#if APP_CAMERA_ENABLED
  static const osThreadAttr_t recorder_attributes = {
      .name="camera_record", .stack_mem=camera_task_stack,
      .stack_size=sizeof(camera_task_stack),
      .cb_mem=&camera_task_control, .cb_size=sizeof(camera_task_control),
      .priority=osPriorityLow
  };
  configASSERT(osThreadNew(CameraSnapshot_Task,NULL,&recorder_attributes)!=NULL);
#if CAMERA_FLOW_MAVLINK
  static const osThreadAttr_t flight_log_attributes = {
      .name = "flight_log", .stack_size = 3072,
      .priority = (osPriority_t)(osPriorityLow - 2)
  };
  configASSERT(osThreadNew(CameraSnapshot_FlightLogTask, NULL, &flight_log_attributes) != NULL);
#endif
#endif
#if PMW3901_FLOW_MAVLINK
  static const osThreadAttr_t pmw3901_attributes = {
      .name = "pmw3901", .stack_size = 1536, .priority = osPriorityLow
  };
  configASSERT(osThreadNew(PMW3901_Task, NULL, &pmw3901_attributes) != NULL);
#endif
  static const osThreadAttr_t uwb_attributes = {
      .name = "uwb_range", .stack_size = 4096, .priority = osPriorityLow
  };
  osThreadId_t uwb_handle = osThreadNew(UWB_RangeTask, NULL, &uwb_attributes);
  /* Optional hardware must not stop GPS/Bluetooth if allocation fails. */
  if (uwb_handle == NULL) UWB_RangeTaskUnavailable();
  (void)uwb_handle;
  /* Fail visibly rather than silently losing a task if allocation fails. */
  configASSERT(defaultTaskHandle != NULL);
  configASSERT(uart_bluetoothHandle != NULL);
  configASSERT(led_blinkHandle != NULL);
  configASSERT(mavlinkTaskHandle != NULL);
  configASSERT(gpsTaskHandle != NULL);
  configASSERT(audio1Handle != NULL);
  configASSERT(thermalTaskHandle != NULL);
  configASSERT(i2c1MutexHandle != NULL);
  configASSERT(LD6002TaskHandle != NULL);

  /* USER CODE END RTOS_THREADS */

}

void StartDefaultTask(void *argument)
{
  /* USER CODE BEGIN StartDefaultTask */
  for (;;)
  {
    osDelay(1000);
  }
  /* USER CODE END StartDefaultTask */
}

void BLUETOOTH(void *argument)
{
  /* USER CODE BEGIN BLUETOOTH */
    char buffer[192];
    FC_Telemetry_t fc = {0};

    for (;;)
    {
        int length;
        const char *readiness = "UNKNOWN (telemetry unavailable)";
        if (MAVLink_GetTelemetry(&fc))
        {
            uint32_t now = (uint32_t)(xTaskGetTickCount() * portTICK_PERIOD_MS);
            readiness = FC_ArmReadiness(&fc, now);
            const char *arm = fc.connected
                ? (fc.armed ? "ARMED" : "DISARMED") : "UNKNOWN";
            if (fc.attitude_count == 0U)
                length = snprintf(buffer, sizeof(buffer), "Arm=%s | Attitude unavailable\r\n", arm);
            else if ((uint32_t)(now - fc.last_attitude_ms) >= 1000U)
                length = snprintf(buffer, sizeof(buffer), "Arm=%s | Attitude stale\r\n", arm);
            else
                length = snprintf(buffer, sizeof(buffer), "Yaw=%ld deg Roll=%ld deg Arm=%s\r\n",
                    (long)(fc.yaw * 57.2957795f), (long)(fc.roll * 57.2957795f), arm);
        }
        else
            length = snprintf(buffer, sizeof(buffer), "Telemetry unavailable\r\n");
        if (length > 0 && (size_t)length < sizeof(buffer))
            AppLog_Write(buffer, (uint16_t)length, 100);

        length = snprintf(buffer, sizeof(buffer), "Arm readiness: %s\r\n", readiness);
        if (length > 0 && (size_t)length < sizeof(buffer))
            AppLog_Write(buffer, (uint16_t)length, 100);

        UWB_RangeSnapshot uwb = {0};
        if (!UWB_RangeGetSnapshot(&uwb))
            length = snprintf(buffer, sizeof(buffer), "UWB: unavailable\r\n");
        else if (uwb.init_result > 0)
            length = snprintf(buffer, sizeof(buffer), "UWB: starting\r\n");
        else if (uwb.init_result < 0)
            length = snprintf(buffer, sizeof(buffer), "UWB: unavailable\r\n");
        else if (uwb.valid && (uint32_t)(HAL_GetTick() - uwb.last_update_ms) < 1000U)
        {
            if (uwb.rssi_valid)
                length = snprintf(buffer, sizeof(buffer), "UWB: %ld.%03ld m | Signal: %d dBm\r\n",
                    (long)(uwb.distance_mm / 1000), (long)(uwb.distance_mm % 1000),
                    (int)(uwb.rssi_q8 / 256));
            else
                length = snprintf(buffer, sizeof(buffer), "UWB: %ld.%03ld m\r\n",
                    (long)(uwb.distance_mm / 1000), (long)(uwb.distance_mm % 1000));
        }
        else
            length = snprintf(buffer, sizeof(buffer), "UWB: no range\r\n");
        if (length > 0 && (size_t)length < sizeof(buffer))
            AppLog_Write(buffer, (uint16_t)length, 100);

        if (uwb.init_result == 0) {
            bool fresh = uwb.valid &&
                (uint32_t)(HAL_GetTick() - uwb.last_update_ms) < 1000U;
            if (!fresh || !uwb.pdoa_valid)
                length = snprintf(buffer, sizeof(buffer), "UWB angle: no valid phase\r\n");
            else {
                /* Integer formatting: embedded printf has no float support. */
                long phase_mdeg = (long)((float)uwb.pdoa_raw * 27.9764548f);
                if (uwb.angle_valid) {
                    long magnitude = uwb.bearing_mdeg < 0 ?
                        -(long)uwb.bearing_mdeg : (long)uwb.bearing_mdeg;
                    length = snprintf(buffer, sizeof(buffer), "UWB angle approx: %s%ld.%01ld deg\r\n",
                        uwb.bearing_mdeg < 0 ? "-" : "+", magnitude / 1000,
                        (magnitude % 1000) / 100);
                }
                else
                    length = snprintf(buffer, sizeof(buffer),
                        "UWB phase: %ld mdeg | bearing: %s\r\n", phase_mdeg,
                        !uwb.pdoa_filtered_valid ? "filter warming up" :
                        uwb.angle_calibrated ? "invalid geometry" : "send uwb zero facing target");
            }
            if (length > 0 && (size_t)length < sizeof(buffer))
                AppLog_Write(buffer, (uint16_t)length, 100);
        }

#if APP_CAMERA_ENABLED
        length = CameraSnapshot_FormatStatus(buffer, sizeof(buffer));
        if (length > 0 && (size_t)length < sizeof(buffer))
            AppLog_Write(buffer, (uint16_t)length, 100);
#endif

        osDelay(1000);
    }
  /* USER CODE END BLUETOOTH */
}

void led_blink1(void *argument)
{
  /* USER CODE BEGIN led_blink1 */
    FC_Telemetry_t fc;
    for (;;) {
        HAL_GPIO_TogglePin(GPIOI, GPIO_PIN_1);
        if (!LED_Strip_IsBusy()) {
            const bool received = MAVLink_GetTelemetry(&fc);
            const uint32_t now = (uint32_t)(xTaskGetTickCount() * portTICK_PERIOD_MS);
            const FC_ArmStatus status = received ? FC_GetArmStatus(&fc, now) : FC_ARM_DISCONNECTED;
            const bool show_green = status == FC_ARM_READY || status == FC_ARM_ALREADY_ARMED;
            uint8_t red = show_green ? 0U : 255U;
            uint8_t green = show_green ? 255U : 0U;
            uint8_t blue = 0U;
            if (status == FC_ARM_ALREADY_ARMED) {
                if (fc.guided_motion == FC_GUIDED_MOTION_FORWARD) {
                    red = 0U;
                    green = 0U;
                    blue = 255U;
                } else if (fc.guided_motion == FC_GUIDED_MOTION_RETURN) {
                    red = 255U;
                    green = 45U;
                    blue = 145U;
                }
            }

            for (uint16_t i = 0; i < STATUS_LED_COUNT; i += STATUS_LED_STEP)
                LED_Strip_Set(i, red, green, blue, 100U);
            LED_Strip_Show();
        }
        osDelay(500);
    }
  /* USER CODE END led_blink1 */
}

void StartMavlinkTask(void *argument)
{
  /* USER CODE BEGIN StartMavlinkTask */
  /* Infinite loop */
  MAVLink_Task();
  /* USER CODE END StartMavlinkTask */
}

void StartGpsTask(void *argument)
{
  /* USER CODE BEGIN StartGpsTask */
  // Keep reception responsive while the lower-priority Bluetooth task prints.
  osThreadSetPriority(osThreadGetId(), osPriorityNormal);
  GPS_RawTask();
  /* USER CODE END StartGpsTask */
}

void audio(void *argument)
{
  /* USER CODE BEGIN audio */
  FC_Telemetry_t telemetry;
  uint32_t last_mode = UINT32_MAX; /* No mode has been announced yet. */
  AudioPlayer_Play("0:/sound1.wav", 20);
  for (;;)
  {

    if (MAVLink_GetTelemetry(&telemetry) &&
        telemetry.heartbeat_count != 0U &&
        telemetry.flight_mode != last_mode)
    {
      /* Remember first, so a missing WAV will not cause repeated attempts. */
      last_mode = telemetry.flight_mode;

      /* ArduPilot Copter mode IDs: 2 = Alt Hold, 5 = Loiter. */
      if (last_mode == 2U)
      {
        AudioPlayer_Play("0:/althold.wav", 100);
      }
      else if (last_mode == 5U)
      {
        AudioPlayer_Play("0:/loiter.wav", 100);
      }
    }
    osDelay(20);
  }
  /* USER CODE END audio */
}

/* USER CODE BEGIN Header_StartThermalTask */
/**
 * @brief Thermal acquisition task; sensor driver has not been supplied yet.
 */
/* USER CODE END Header_StartThermalTask */
void StartThermalTask(void *argument)
{
  /* USER CODE BEGIN StartThermalTask */
  (void)argument;
  /* Integrate camera initialization and acquisition here using hi2c1.
   * Acquire i2c1MutexHandle around each complete I2C operation; release it
   * before temperature calculations, frame waits, logging or display work.
   * There is deliberately no camera traffic until its driver is imported.
    OV2640 SCCB and MLX90640 register operations share this mutex. */
   MLX_I2C_DmaInit();
   MLX90640_I2CInit();
  thermal_test_run();

  /* USER CODE END StartThermalTask */
}

/* USER CODE BEGIN Application */
void LD6002(void *argument)
{
  /* USER CODE BEGIN LD6002_Task */
  LD6002_Task(argument);      /* never returns */
  for (;;) osDelay(1000);
  /* USER CODE END LD6002_Task */
}
/* USER CODE END Application */
